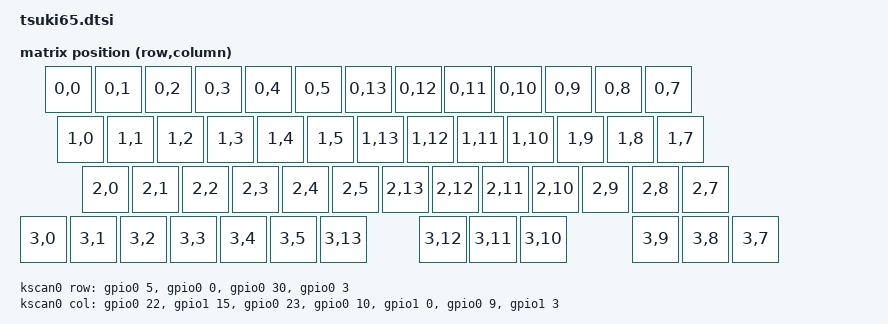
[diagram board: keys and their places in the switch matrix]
#include <zephyr/dt-bindings/gpio/nordic-nrf-gpio.h>
#include <dt-bindings/zmk/matrix_transform.h>
#include <physical_layouts.dtsi>

/* generated by scripts/gen_fw.py -- 52 keys, row-staggered; the 14 mm trackball is not in the matrix */

/ {
    chosen {
        zmk,physical-layout = &physical_layout0;
        zmk,kscan = &kscan0;
        zmk,battery = &non_lipo_battery;
    };

    default_transform: keymap_transform_0 {
        compatible = "zmk,matrix-transform";
        columns = <14>;
        rows = <4>;
        map = <
            RC(0,0) RC(0,1) RC(0,2) RC(0,3) RC(0,4) RC(0,5) RC(0,13) RC(0,12) RC(0,11) RC(0,10) RC(0,9) RC(0,8) RC(0,7)
            RC(1,0) RC(1,1) RC(1,2) RC(1,3) RC(1,4) RC(1,5) RC(1,13) RC(1,12) RC(1,11) RC(1,10) RC(1,9) RC(1,8) RC(1,7)
            RC(2,0) RC(2,1) RC(2,2) RC(2,3) RC(2,4) RC(2,5) RC(2,13) RC(2,12) RC(2,11) RC(2,10) RC(2,9) RC(2,8) RC(2,7)
            RC(3,0) RC(3,1) RC(3,2) RC(3,3) RC(3,4) RC(3,5) RC(3,13) RC(3,12) RC(3,11) RC(3,10) RC(3,9) RC(3,8) RC(3,7)
        >;
    };

    physical_layout0: physical_layout_0 {
        compatible = "zmk,physical-layout";
        display-name = "tsuki65";
        kscan = <&kscan0>;
        transform = <&default_transform>;
        keys  //                     w   h     x     y rot rx ry
            = <&key_physical_attrs 100 100    50     0 0 0 0>
            , <&key_physical_attrs 100 100   150     0 0 0 0>
            , <&key_physical_attrs 100 100   250     0 0 0 0>
            , <&key_physical_attrs 100 100   350     0 0 0 0>
            , <&key_physical_attrs 100 100   450     0 0 0 0>
            , <&key_physical_attrs 100 100   550     0 0 0 0>
            , <&key_physical_attrs 100 100   650     0 0 0 0>
            , <&key_physical_attrs 100 100   750     0 0 0 0>
            , <&key_physical_attrs 100 100   850     0 0 0 0>
            , <&key_physical_attrs 100 100   950     0 0 0 0>
            , <&key_physical_attrs 100 100  1050     0 0 0 0>
            , <&key_physical_attrs 100 100  1150     0 0 0 0>
            , <&key_physical_attrs 100 100  1250     0 0 0 0>
            , <&key_physical_attrs 100 100    75   100 0 0 0>
            , <&key_physical_attrs 100 100   175   100 0 0 0>
            , <&key_physical_attrs 100 100   275   100 0 0 0>
            , <&key_physical_attrs 100 100   375   100 0 0 0>
            , <&key_physical_attrs 100 100   475   100 0 0 0>
            , <&key_physical_attrs 100 100   575   100 0 0 0>
            , <&key_physical_attrs 100 100   675   100 0 0 0>
            , <&key_physical_attrs 100 100   775   100 0 0 0>
            , <&key_physical_attrs 100 100   875   100 0 0 0>
            , <&key_physical_attrs 100 100   975   100 0 0 0>
            , <&key_physical_attrs 100 100  1075   100 0 0 0>
            , <&key_physical_attrs 100 100  1175   100 0 0 0>
            , <&key_physical_attrs 100 100  1275   100 0 0 0>
            , <&key_physical_attrs 100 100   125   200 0 0 0>
            , <&key_physical_attrs 100 100   225   200 0 0 0>
            , <&key_physical_attrs 100 100   325   200 0 0 0>
            , <&key_physical_attrs 100 100   425   200 0 0 0>
            , <&key_physical_attrs 100 100   525   200 0 0 0>
            , <&key_physical_attrs 100 100   625   200 0 0 0>
            , <&key_physical_attrs 100 100   725   200 0 0 0>
            , <&key_physical_attrs 100 100   825   200 0 0 0>
            , <&key_physical_attrs 100 100   925   200 0 0 0>
            , <&key_physical_attrs 100 100  1025   200 0 0 0>
            , <&key_physical_attrs 100 100  1125   200 0 0 0>
            , <&key_physical_attrs 100 100  1225   200 0 0 0>
            , <&key_physical_attrs 100 100  1325   200 0 0 0>
            , <&key_physical_attrs 100 100     0   300 0 0 0>
            , <&key_physical_attrs 100 100   100   300 0 0 0>
            , <&key_physical_attrs 100 100   200   300 0 0 0>
            , <&key_physical_attrs 100 100   300   300 0 0 0>
            , <&key_physical_attrs 100 100   400   300 0 0 0>
            , <&key_physical_attrs 100 100   500   300 0 0 0>
            , <&key_physical_attrs 100 100   600   300 0 0 0>
            , <&key_physical_attrs 100 100   800   300 0 0 0>
            , <&key_physical_attrs 100 100   900   300 0 0 0>
            , <&key_physical_attrs 100 100  1000   300 0 0 0>
            , <&key_physical_attrs 100 100  1225   300 0 0 0>
            , <&key_physical_attrs 100 100  1325   300 0 0 0>
            , <&key_physical_attrs 100 100  1425   300 0 0 0>
            ;
    };

    /* BMP Boost pin assignment is identical to torabo-tsuki LP */
    kscan0: kscan {
        compatible = "zmk,kscan-gpio-matrix";
        diode-direction = "row2col";
        col-gpios
            = <&gpio0 22 (GPIO_ACTIVE_HIGH | GPIO_PULL_DOWN)>,
            <&gpio1 15   (GPIO_ACTIVE_HIGH | GPIO_PULL_DOWN)>,
            <&gpio0 23   (GPIO_ACTIVE_HIGH | GPIO_PULL_DOWN)>,
            <&gpio0 10   (GPIO_ACTIVE_HIGH | GPIO_PULL_DOWN)>,
            <&gpio1 0    (GPIO_ACTIVE_HIGH | GPIO_PULL_DOWN)>,
            <&gpio0 9    (GPIO_ACTIVE_HIGH | GPIO_PULL_DOWN)>,
            <&gpio1 3    (GPIO_ACTIVE_HIGH | GPIO_PULL_DOWN)>
            ;
        row-gpios
            = <&gpio0 5 (GPIO_ACTIVE_HIGH)>,
            <&gpio0 0  (GPIO_ACTIVE_HIGH)>,
            <&gpio0 30 (GPIO_ACTIVE_HIGH)>,
            <&gpio0 3  (GPIO_ACTIVE_HIGH)>
            ;   /* ROW4 (gpio1 14, BMP pin 17) unused: 4 rows */
        wakeup-source;
    };

    leds {
        compatible = "gpio-leds";
        status_led: status_led {
            gpios = <&bmp 2 GPIO_ACTIVE_HIGH>;
            label = "Status LED";
        };
    };

    status_led_device: status_led_device {
        compatible = "zmk,status-led";
        led = <&status_led>;
    };

    bootloader_trigger: bootloader_trigger {
        compatible = "zmk,cdc-acm-bootloader-trigger";
    };

    pointing_listener: pointing_listener {
        compatible = "zmk,input-listener";
        status = "disabled";
    };

    vbatt: vbatt {
        status = "disabled";
    };
    non_lipo_battery: non_lipo_battery {
        compatible = "zmk,non-lipo-battery";
        io-channels = <&adc 4>;
    };
};

&pinctrl {
    spi0_default: spi0_default {
        group1 {
            psels = <NRF_PSEL(SPIM_SCK, 0, 18)>,
                    <NRF_PSEL(SPIM_MOSI, 0, 16)>,
                    <NRF_PSEL(SPIM_MISO, 0, 16)>;
        };
    };
    spi0_sleep: spi0_sleep {
        group1 {
            psels = <NRF_PSEL(SPIM_SCK, 0, 18)>,
                    <NRF_PSEL(SPIM_MOSI, 0, 16)>,
                    <NRF_PSEL(SPIM_MISO, 0, 16)>;
        };
        low-power-enable;
    };
};
